AUTOSAR XML (schema 4-2-2)
package /STELLANTIS/EPT/SASWCs
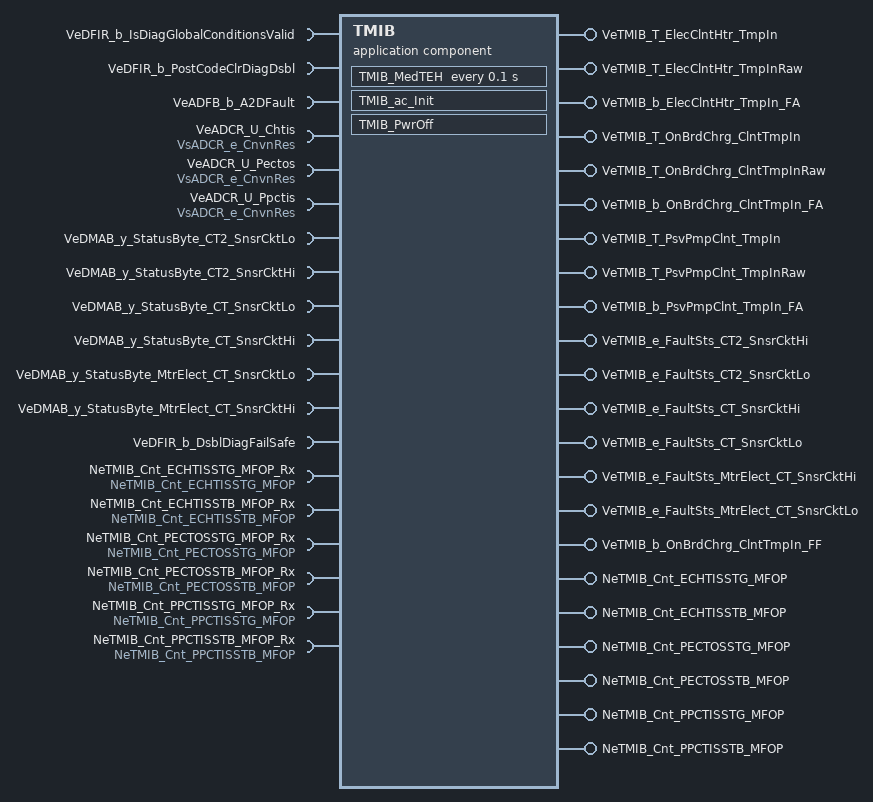
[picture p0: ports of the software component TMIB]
  application sw component type TMIB
    13 x require port:
      VeDFIR_b_IsDiagGlobalConditionsValid: variation-point={short-label=vpVeDFIR_b_IsDiagGlobalConditionsValid, sw-syscond=1}, nonqueued-receiver-com-spec{data-element=Value, init-value=0}, required-interface=VeDFIR_b_IsDiagGlobalConditionsValid
      VeDFIR_b_PostCodeClrDiagDsbl: variation-point={short-label=vpVeDFIR_b_PostCodeClrDiagDsbl, sw-syscond=1}, nonqueued-receiver-com-spec{data-element=Value, init-value=0}, required-interface=VeDFIR_b_PostCodeClrDiagDsbl
      VeADFB_b_A2DFault: variation-point={short-label=vpVeADFB_b_A2DFault, sw-syscond=1}, nonqueued-receiver-com-spec{data-element=Value, init-value=0}, required-interface=VeADFB_b_A2DFault
      VeADCR_U_Chtis: variation-point={short-label=vpVeADCR_U_Chtis, sw-syscond=1}, nonqueued-receiver-com-spec{data-element=VsADCR_e_CnvnRes, init-value={short-label=DefaultInitValue_IDTRAdcInpResData, fields=[0, 0]}}, required-interface=VsADCR_e_CnvnRes
      VeADCR_U_Pectos: variation-point={short-label=vpVeADCR_U_Pectos, sw-syscond=1}, nonqueued-receiver-com-spec{data-element=VsADCR_e_CnvnRes, init-value={short-label=DefaultInitValue_IDTRAdcInpResData, fields=[0, 0]}}, required-interface=VsADCR_e_CnvnRes
      VeADCR_U_Ppctis: variation-point={short-label=vpVeADCR_U_Ppctis, sw-syscond=1}, nonqueued-receiver-com-spec{data-element=VsADCR_e_CnvnRes, init-value={short-label=DefaultInitValue_IDTRAdcInpResData, fields=[0, 0]}}, required-interface=VsADCR_e_CnvnRes
      VeDMAB_y_StatusByte_CT2_SnsrCktLo: variation-point={short-label=vpVeDMAB_y_StatusByte_CT2_SnsrCktLo, sw-syscond=1}, nonqueued-receiver-com-spec{data-element=Value, init-value=0}, required-interface=VeDMAB_y_StatusByte_CT2_SnsrCktLo
      VeDMAB_y_StatusByte_CT2_SnsrCktHi: variation-point={short-label=vpVeDMAB_y_StatusByte_CT2_SnsrCktHi, sw-syscond=1}, nonqueued-receiver-com-spec{data-element=Value, init-value=0}, required-interface=VeDMAB_y_StatusByte_CT2_SnsrCktHi
      VeDMAB_y_StatusByte_CT_SnsrCktLo: variation-point={short-label=vpVeDMAB_y_StatusByte_CT_SnsrCktLo, sw-syscond=1}, nonqueued-receiver-com-spec{data-element=Value, init-value=0}, required-interface=VeDMAB_y_StatusByte_CT_SnsrCktLo
      VeDMAB_y_StatusByte_CT_SnsrCktHi: variation-point={short-label=vpVeDMAB_y_StatusByte_CT_SnsrCktHi, sw-syscond=1}, nonqueued-receiver-com-spec{data-element=Value, init-value=0}, required-interface=VeDMAB_y_StatusByte_CT_SnsrCktHi
      VeDMAB_y_StatusByte_MtrElect_CT_SnsrCktLo: variation-point={short-label=vpVeDMAB_y_StatusByte_MtrElect_CT_SnsrCktLo, sw-syscond=1}, nonqueued-receiver-com-spec{data-element=Value, init-value=0}, required-interface=VeDMAB_y_StatusByte_MtrElect_CT_SnsrCktLo
      VeDMAB_y_StatusByte_MtrElect_CT_SnsrCktHi: variation-point={short-label=vpVeDMAB_y_StatusByte_MtrElect_CT_SnsrCktHi, sw-syscond=1}, nonqueued-receiver-com-spec{data-element=Value, init-value=0}, required-interface=VeDMAB_y_StatusByte_MtrElect_CT_SnsrCktHi
      VeDFIR_b_DsblDiagFailSafe: variation-point={short-label=vpVeDFIR_b_DsblDiagFailSafe, sw-syscond=1}, nonqueued-receiver-com-spec{data-element=Value, init-value=0}, required-interface=VeDFIR_b_DsblDiagFailSafe
    16 x provide port:
      VeTMIB_T_ElecClntHtr_TmpIn: variation-point={short-label=vpVeTMIB_T_ElecClntHtr_TmpIn, sw-syscond=1}, nonqueued-sender-com-spec{data-element=Value, init-value=0}, provided-interface=VeTMIB_T_ElecClntHtr_TmpIn
      VeTMIB_T_ElecClntHtr_TmpInRaw: variation-point={short-label=vpVeTMIB_T_ElecClntHtr_TmpInRaw, sw-syscond=1}, nonqueued-sender-com-spec{data-element=Value, init-value=0}, provided-interface=VeTMIB_T_ElecClntHtr_TmpInRaw
      VeTMIB_b_ElecClntHtr_TmpIn_FA: variation-point={short-label=vpVeTMIB_b_ElecClntHtr_TmpIn_FA, sw-syscond=1}, nonqueued-sender-com-spec{data-element=Value, init-value=0}, provided-interface=VeTMIB_b_ElecClntHtr_TmpIn_FA
      VeTMIB_T_OnBrdChrg_ClntTmpIn: variation-point={short-label=vpVeTMIB_T_OnBrdChrg_ClntTmpIn, sw-syscond=1}, nonqueued-sender-com-spec{data-element=Value, init-value=0}, provided-interface=VeTMIB_T_OnBrdChrg_ClntTmpIn
      VeTMIB_T_OnBrdChrg_ClntTmpInRaw: variation-point={short-label=vpVeTMIB_T_OnBrdChrg_ClntTmpInRaw, sw-syscond=1}, nonqueued-sender-com-spec{data-element=Value, init-value=0}, provided-interface=VeTMIB_T_OnBrdChrg_ClntTmpInRaw
      VeTMIB_b_OnBrdChrg_ClntTmpIn_FA: variation-point={short-label=vpVeTMIB_b_OnBrdChrg_ClntTmpIn_FA, sw-syscond=1}, nonqueued-sender-com-spec{data-element=Value, init-value=0}, provided-interface=VeTMIB_b_OnBrdChrg_ClntTmpIn_FA
      VeTMIB_T_PsvPmpClnt_TmpIn: variation-point={short-label=vpVeTMIB_T_PsvPmpClnt_TmpIn, sw-syscond=1}, nonqueued-sender-com-spec{data-element=Value, init-value=0}, provided-interface=VeTMIB_T_PsvPmpClnt_TmpIn
      VeTMIB_T_PsvPmpClnt_TmpInRaw: variation-point={short-label=vpVeTMIB_T_PsvPmpClnt_TmpInRaw, sw-syscond=1}, nonqueued-sender-com-spec{data-element=Value, init-value=0}, provided-interface=VeTMIB_T_PsvPmpClnt_TmpInRaw
      VeTMIB_b_PsvPmpClnt_TmpIn_FA: variation-point={short-label=vpVeTMIB_b_PsvPmpClnt_TmpIn_FA, sw-syscond=1}, nonqueued-sender-com-spec{data-element=Value, init-value=0}, provided-interface=VeTMIB_b_PsvPmpClnt_TmpIn_FA
      VeTMIB_e_FaultSts_CT2_SnsrCktHi: variation-point={short-label=vpVeTMIB_e_FaultSts_CT2_SnsrCktHi, sw-syscond=1}, nonqueued-sender-com-spec{data-element=Value, init-value=CeDFIB_e_Init}, provided-interface=VeTMIB_e_FaultSts_CT2_SnsrCktHi
      VeTMIB_e_FaultSts_CT2_SnsrCktLo: variation-point={short-label=vpVeTMIB_e_FaultSts_CT2_SnsrCktLo, sw-syscond=1}, nonqueued-sender-com-spec{data-element=Value, init-value=CeDFIB_e_Init}, provided-interface=VeTMIB_e_FaultSts_CT2_SnsrCktLo
      VeTMIB_e_FaultSts_CT_SnsrCktHi: variation-point={short-label=vpVeTMIB_e_FaultSts_CT_SnsrCktHi, sw-syscond=1}, nonqueued-sender-com-spec{data-element=Value, init-value=CeDFIB_e_Init}, provided-interface=VeTMIB_e_FaultSts_CT_SnsrCktHi
      VeTMIB_e_FaultSts_CT_SnsrCktLo: variation-point={short-label=vpVeTMIB_e_FaultSts_CT_SnsrCktLo, sw-syscond=1}, nonqueued-sender-com-spec{data-element=Value, init-value=CeDFIB_e_Init}, provided-interface=VeTMIB_e_FaultSts_CT_SnsrCktLo
      VeTMIB_e_FaultSts_MtrElect_CT_SnsrCktHi: variation-point={short-label=vpVeTMIB_e_FaultSts_MtrElect_CT_SnsrCktHi, sw-syscond=1}, nonqueued-sender-com-spec{data-element=Value, init-value=CeDFIB_e_Init}, provided-interface=VeTMIB_e_FaultSts_MtrElect_CT_SnsrCktHi
      VeTMIB_e_FaultSts_MtrElect_CT_SnsrCktLo: variation-point={short-label=vpVeTMIB_e_FaultSts_MtrElect_CT_SnsrCktLo, sw-syscond=1}, nonqueued-sender-com-spec{data-element=Value, init-value=CeDFIB_e_Init}, provided-interface=VeTMIB_e_FaultSts_MtrElect_CT_SnsrCktLo
      VeTMIB_b_OnBrdChrg_ClntTmpIn_FF: variation-point={short-label=vpVeTMIB_b_OnBrdChrg_ClntTmpIn_FF, sw-syscond=1}, nonqueued-sender-com-spec{data-element=Value, init-value=0}, provided-interface=VeTMIB_b_OnBrdChrg_ClntTmpIn_FF
    6 x require port:
      NeTMIB_Cnt_ECHTISSTG_MFOP_Rx: variation-point={short-label=vpNeTMIB_Cnt_ECHTISSTG_MFOP_Rx, sw-syscond=1}, nv-require-com-spec{init-value=0, variable=NeTMIB_Cnt_ECHTISSTG_MFOP}, required-interface=NeTMIB_Cnt_ECHTISSTG_MFOP
      NeTMIB_Cnt_ECHTISSTB_MFOP_Rx: variation-point={short-label=vpNeTMIB_Cnt_ECHTISSTB_MFOP_Rx, sw-syscond=1}, nv-require-com-spec{init-value=0, variable=NeTMIB_Cnt_ECHTISSTB_MFOP}, required-interface=NeTMIB_Cnt_ECHTISSTB_MFOP
      NeTMIB_Cnt_PECTOSSTG_MFOP_Rx: variation-point={short-label=vpNeTMIB_Cnt_PECTOSSTG_MFOP_Rx, sw-syscond=1}, nv-require-com-spec{init-value=0, variable=NeTMIB_Cnt_PECTOSSTG_MFOP}, required-interface=NeTMIB_Cnt_PECTOSSTG_MFOP
      NeTMIB_Cnt_PECTOSSTB_MFOP_Rx: variation-point={short-label=vpNeTMIB_Cnt_PECTOSSTB_MFOP_Rx, sw-syscond=1}, nv-require-com-spec{init-value=0, variable=NeTMIB_Cnt_PECTOSSTB_MFOP}, required-interface=NeTMIB_Cnt_PECTOSSTB_MFOP
      NeTMIB_Cnt_PPCTISSTG_MFOP_Rx: variation-point={short-label=vpNeTMIB_Cnt_PPCTISSTG_MFOP_Rx, sw-syscond=1}, nv-require-com-spec{init-value=0, variable=NeTMIB_Cnt_PPCTISSTG_MFOP}, required-interface=NeTMIB_Cnt_PPCTISSTG_MFOP
      NeTMIB_Cnt_PPCTISSTB_MFOP_Rx: variation-point={short-label=vpNeTMIB_Cnt_PPCTISSTB_MFOP_Rx, sw-syscond=1}, nv-require-com-spec{init-value=0, variable=NeTMIB_Cnt_PPCTISSTB_MFOP}, required-interface=NeTMIB_Cnt_PPCTISSTB_MFOP
    6 x provide port:
      NeTMIB_Cnt_ECHTISSTG_MFOP: nv-provide-com-spec{ram-block-init-value=0, variable=NeTMIB_Cnt_ECHTISSTG_MFOP}, provided-interface=NeTMIB_Cnt_ECHTISSTG_MFOP
      NeTMIB_Cnt_ECHTISSTB_MFOP: nv-provide-com-spec{ram-block-init-value=0, variable=NeTMIB_Cnt_ECHTISSTB_MFOP}, provided-interface=NeTMIB_Cnt_ECHTISSTB_MFOP
      NeTMIB_Cnt_PECTOSSTG_MFOP: nv-provide-com-spec{ram-block-init-value=0, variable=NeTMIB_Cnt_PECTOSSTG_MFOP}, provided-interface=NeTMIB_Cnt_PECTOSSTG_MFOP
      NeTMIB_Cnt_PECTOSSTB_MFOP: nv-provide-com-spec{ram-block-init-value=0, variable=NeTMIB_Cnt_PECTOSSTB_MFOP}, provided-interface=NeTMIB_Cnt_PECTOSSTB_MFOP
      NeTMIB_Cnt_PPCTISSTG_MFOP: nv-provide-com-spec{ram-block-init-value=0, variable=NeTMIB_Cnt_PPCTISSTG_MFOP}, provided-interface=NeTMIB_Cnt_PPCTISSTG_MFOP
      NeTMIB_Cnt_PPCTISSTB_MFOP: nv-provide-com-spec{ram-block-init-value=0, variable=NeTMIB_Cnt_PPCTISSTB_MFOP}, provided-interface=NeTMIB_Cnt_PPCTISSTB_MFOP
    behavior IB_TMIB: data-type-mapping=[msADTtoIDTMapping, ADTtoIDTMapping], handle-termination-and-restart=NO-SUPPORT
      timing event Event_MedTEH: start-on-event=TMIB_MedTEH, period=0.1
      init event Event_TMIB_ac_Init: start-on-event=TMIB_ac_Init
      init event Event_PwrOff: start-on-event=TMIB_PwrOff
      runnable TMIB_ac_Init
        data-receive-point-by-arguments:
          6 x access:
            IN_NeTMIB_Cnt_ECHTISSTB_MFOP_Rx_NeTMIB_Cnt_ECHTISSTB_MFOP: accessed-variable=NeTMIB_Cnt_ECHTISSTB_MFOP_Rx.NeTMIB_Cnt_ECHTISSTB_MFOP, variation-point={short-label=vpIN_NeTMIB_Cnt_ECHTISSTB_MFOP_Rx_NeTMIB_Cnt_ECHTISSTB_MFOP, sw-syscond=1}
            IN_NeTMIB_Cnt_ECHTISSTG_MFOP_Rx_NeTMIB_Cnt_ECHTISSTG_MFOP: accessed-variable=NeTMIB_Cnt_ECHTISSTG_MFOP_Rx.NeTMIB_Cnt_ECHTISSTG_MFOP, variation-point={short-label=vpIN_NeTMIB_Cnt_ECHTISSTG_MFOP_Rx_NeTMIB_Cnt_ECHTISSTG_MFOP, sw-syscond=1}
            IN_NeTMIB_Cnt_PECTOSSTB_MFOP_Rx_NeTMIB_Cnt_PECTOSSTB_MFOP: accessed-variable=NeTMIB_Cnt_PECTOSSTB_MFOP_Rx.NeTMIB_Cnt_PECTOSSTB_MFOP, variation-point={short-label=vpIN_NeTMIB_Cnt_PECTOSSTB_MFOP_Rx_NeTMIB_Cnt_PECTOSSTB_MFOP, sw-syscond=1}
            IN_NeTMIB_Cnt_PECTOSSTG_MFOP_Rx_NeTMIB_Cnt_PECTOSSTG_MFOP: accessed-variable=NeTMIB_Cnt_PECTOSSTG_MFOP_Rx.NeTMIB_Cnt_PECTOSSTG_MFOP, variation-point={short-label=vpIN_NeTMIB_Cnt_PECTOSSTG_MFOP_Rx_NeTMIB_Cnt_PECTOSSTG_MFOP, sw-syscond=1}
            IN_NeTMIB_Cnt_PPCTISSTB_MFOP_Rx_NeTMIB_Cnt_PPCTISSTB_MFOP: accessed-variable=NeTMIB_Cnt_PPCTISSTB_MFOP_Rx.NeTMIB_Cnt_PPCTISSTB_MFOP, variation-point={short-label=vpIN_NeTMIB_Cnt_PPCTISSTB_MFOP_Rx_NeTMIB_Cnt_PPCTISSTB_MFOP, sw-syscond=1}
            IN_NeTMIB_Cnt_PPCTISSTG_MFOP_Rx_NeTMIB_Cnt_PPCTISSTG_MFOP: accessed-variable=NeTMIB_Cnt_PPCTISSTG_MFOP_Rx.NeTMIB_Cnt_PPCTISSTG_MFOP, variation-point={short-label=vpIN_NeTMIB_Cnt_PPCTISSTG_MFOP_Rx_NeTMIB_Cnt_PPCTISSTG_MFOP, sw-syscond=1}
        data-send-points:
          12 x access:
            OUT_VeTMIB_T_ElecClntHtr_TmpInRaw_Value: accessed-variable=VeTMIB_T_ElecClntHtr_TmpInRaw.Value, variation-point={short-label=vpOUT_VeTMIB_T_ElecClntHtr_TmpInRaw_Value, sw-syscond=1}
            OUT_VeTMIB_T_ElecClntHtr_TmpIn_Value: accessed-variable=VeTMIB_T_ElecClntHtr_TmpIn.Value, variation-point={short-label=vpOUT_VeTMIB_T_ElecClntHtr_TmpIn_Value, sw-syscond=1}
            OUT_VeTMIB_e_FaultSts_CT2_SnsrCktHi_Value: accessed-variable=VeTMIB_e_FaultSts_CT2_SnsrCktHi.Value, variation-point={short-label=vpOUT_VeTMIB_e_FaultSts_CT2_SnsrCktHi_Value, sw-syscond=1}
            OUT_VeTMIB_e_FaultSts_CT2_SnsrCktLo_Value: accessed-variable=VeTMIB_e_FaultSts_CT2_SnsrCktLo.Value, variation-point={short-label=vpOUT_VeTMIB_e_FaultSts_CT2_SnsrCktLo_Value, sw-syscond=1}
            OUT_VeTMIB_T_OnBrdChrg_ClntTmpIn_Value: accessed-variable=VeTMIB_T_OnBrdChrg_ClntTmpIn.Value, variation-point={short-label=vpOUT_VeTMIB_T_OnBrdChrg_ClntTmpIn_Value, sw-syscond=1}
            OUT_VeTMIB_T_OnBrdChrg_ClntTmpInRaw_Value: accessed-variable=VeTMIB_T_OnBrdChrg_ClntTmpInRaw.Value, variation-point={short-label=vpOUT_VeTMIB_T_OnBrdChrg_ClntTmpInRaw_Value, sw-syscond=1}
            OUT_VeTMIB_e_FaultSts_CT_SnsrCktHi_Value: accessed-variable=VeTMIB_e_FaultSts_CT_SnsrCktHi.Value, variation-point={short-label=vpOUT_VeTMIB_e_FaultSts_CT_SnsrCktHi_Value, sw-syscond=1}
            OUT_VeTMIB_e_FaultSts_CT_SnsrCktLo_Value: accessed-variable=VeTMIB_e_FaultSts_CT_SnsrCktLo.Value, variation-point={short-label=vpOUT_VeTMIB_e_FaultSts_CT_SnsrCktLo_Value, sw-syscond=1}
            OUT_VeTMIB_T_PsvPmpClnt_TmpIn_Value: accessed-variable=VeTMIB_T_PsvPmpClnt_TmpIn.Value, variation-point={short-label=vpOUT_VeTMIB_T_PsvPmpClnt_TmpIn_Value, sw-syscond=1}
            OUT_VeTMIB_T_PsvPmpClnt_TmpInRaw_Value: accessed-variable=VeTMIB_T_PsvPmpClnt_TmpInRaw.Value, variation-point={short-label=vpOUT_VeTMIB_T_PsvPmpClnt_TmpInRaw_Value, sw-syscond=1}
            OUT_VeTMIB_e_FaultSts_MtrElect_CT_SnsrCktHi_Value: accessed-variable=VeTMIB_e_FaultSts_MtrElect_CT_SnsrCktHi.Value, variation-point={short-label=vpOUT_VeTMIB_e_FaultSts_MtrElect_CT_SnsrCktHi_Value, sw-syscond=1}
            OUT_VeTMIB_e_FaultSts_MtrElect_CT_SnsrCktLo_Value: accessed-variable=VeTMIB_e_FaultSts_MtrElect_CT_SnsrCktLo.Value, variation-point={short-label=vpOUT_VeTMIB_e_FaultSts_MtrElect_CT_SnsrCktLo_Value, sw-syscond=1}
      runnable TMIB_MedTEH
        data-receive-point-by-arguments:
          13 x access:
            IN_VeADCR_U_Chtis_VsADCR_e_CnvnRes: accessed-variable=VeADCR_U_Chtis.VsADCR_e_CnvnRes, variation-point={short-label=vpIN_VeADCR_U_Chtis_VsADCR_e_CnvnRes, sw-syscond=1}
            IN_VeADCR_U_Pectos_VsADCR_e_CnvnRes: accessed-variable=VeADCR_U_Pectos.VsADCR_e_CnvnRes, variation-point={short-label=vpIN_VeADCR_U_Pectos_VsADCR_e_CnvnRes, sw-syscond=1}
            IN_VeADCR_U_Ppctis_VsADCR_e_CnvnRes: accessed-variable=VeADCR_U_Ppctis.VsADCR_e_CnvnRes, variation-point={short-label=vpIN_VeADCR_U_Ppctis_VsADCR_e_CnvnRes, sw-syscond=1}
            IN_VeADFB_b_A2DFault_Value: accessed-variable=VeADFB_b_A2DFault.Value, variation-point={short-label=vpIN_VeADFB_b_A2DFault_Value, sw-syscond=1}
            IN_VeDFIR_b_DsblDiagFailSafe_Value: accessed-variable=VeDFIR_b_DsblDiagFailSafe.Value, variation-point={short-label=vpIN_VeDFIR_b_DsblDiagFailSafe_Value, sw-syscond=1}
            IN_VeDFIR_b_IsDiagGlobalConditionsValid_Value: accessed-variable=VeDFIR_b_IsDiagGlobalConditionsValid.Value, variation-point={short-label=vpIN_VeDFIR_b_IsDiagGlobalConditionsValid_Value, sw-syscond=1}
            IN_VeDFIR_b_PostCodeClrDiagDsbl_Value: accessed-variable=VeDFIR_b_PostCodeClrDiagDsbl.Value, variation-point={short-label=vpIN_VeDFIR_b_PostCodeClrDiagDsbl_Value, sw-syscond=1}
            IN_VeDMAB_y_StatusByte_CT2_SnsrCktHi_Value: accessed-variable=VeDMAB_y_StatusByte_CT2_SnsrCktHi.Value, variation-point={short-label=vpIN_VeDMAB_y_StatusByte_CT2_SnsrCktHi_Value, sw-syscond=1}
            IN_VeDMAB_y_StatusByte_CT2_SnsrCktLo_Value: accessed-variable=VeDMAB_y_StatusByte_CT2_SnsrCktLo.Value, variation-point={short-label=vpIN_VeDMAB_y_StatusByte_CT2_SnsrCktLo_Value, sw-syscond=1}
            IN_VeDMAB_y_StatusByte_CT_SnsrCktHi_Value: accessed-variable=VeDMAB_y_StatusByte_CT_SnsrCktHi.Value, variation-point={short-label=vpIN_VeDMAB_y_StatusByte_CT_SnsrCktHi_Value, sw-syscond=1}
            IN_VeDMAB_y_StatusByte_CT_SnsrCktLo_Value: accessed-variable=VeDMAB_y_StatusByte_CT_SnsrCktLo.Value, variation-point={short-label=vpIN_VeDMAB_y_StatusByte_CT_SnsrCktLo_Value, sw-syscond=1}
            IN_VeDMAB_y_StatusByte_MtrElect_CT_SnsrCktHi_Value: accessed-variable=VeDMAB_y_StatusByte_MtrElect_CT_SnsrCktHi.Value, variation-point={short-label=vpIN_VeDMAB_y_StatusByte_MtrElect_CT_SnsrCktHi_Value, sw-syscond=1}
            IN_VeDMAB_y_StatusByte_MtrElect_CT_SnsrCktLo_Value: accessed-variable=VeDMAB_y_StatusByte_MtrElect_CT_SnsrCktLo.Value, variation-point={short-label=vpIN_VeDMAB_y_StatusByte_MtrElect_CT_SnsrCktLo_Value, sw-syscond=1}
        data-send-points:
          16 x access:
            OUT_VeTMIB_b_ElecClntHtr_TmpIn_FA_Value: accessed-variable=VeTMIB_b_ElecClntHtr_TmpIn_FA.Value, variation-point={short-label=vpOUT_VeTMIB_b_ElecClntHtr_TmpIn_FA_Value, sw-syscond=1}
            OUT_VeTMIB_T_ElecClntHtr_TmpInRaw_Value: accessed-variable=VeTMIB_T_ElecClntHtr_TmpInRaw.Value, variation-point={short-label=vpOUT_VeTMIB_T_ElecClntHtr_TmpInRaw_Value, sw-syscond=1}
            OUT_VeTMIB_T_ElecClntHtr_TmpIn_Value: accessed-variable=VeTMIB_T_ElecClntHtr_TmpIn.Value, variation-point={short-label=vpOUT_VeTMIB_T_ElecClntHtr_TmpIn_Value, sw-syscond=1}
            OUT_VeTMIB_b_OnBrdChrg_ClntTmpIn_FA_Value: accessed-variable=VeTMIB_b_OnBrdChrg_ClntTmpIn_FA.Value, variation-point={short-label=vpOUT_VeTMIB_b_OnBrdChrg_ClntTmpIn_FA_Value, sw-syscond=1}
            OUT_VeTMIB_T_OnBrdChrg_ClntTmpInRaw_Value: accessed-variable=VeTMIB_T_OnBrdChrg_ClntTmpInRaw.Value, variation-point={short-label=vpOUT_VeTMIB_T_OnBrdChrg_ClntTmpInRaw_Value, sw-syscond=1}
            OUT_VeTMIB_T_OnBrdChrg_ClntTmpIn_Value: accessed-variable=VeTMIB_T_OnBrdChrg_ClntTmpIn.Value, variation-point={short-label=vpOUT_VeTMIB_T_OnBrdChrg_ClntTmpIn_Value, sw-syscond=1}
            OUT_VeTMIB_b_PsvPmpClnt_TmpIn_FA_Value: accessed-variable=VeTMIB_b_PsvPmpClnt_TmpIn_FA.Value, variation-point={short-label=vpOUT_VeTMIB_b_PsvPmpClnt_TmpIn_FA_Value, sw-syscond=1}
            OUT_VeTMIB_T_PsvPmpClnt_TmpInRaw_Value: accessed-variable=VeTMIB_T_PsvPmpClnt_TmpInRaw.Value, variation-point={short-label=vpOUT_VeTMIB_T_PsvPmpClnt_TmpInRaw_Value, sw-syscond=1}
            OUT_VeTMIB_T_PsvPmpClnt_TmpIn_Value: accessed-variable=VeTMIB_T_PsvPmpClnt_TmpIn.Value, variation-point={short-label=vpOUT_VeTMIB_T_PsvPmpClnt_TmpIn_Value, sw-syscond=1}
            OUT_VeTMIB_e_FaultSts_CT2_SnsrCktHi_Value: accessed-variable=VeTMIB_e_FaultSts_CT2_SnsrCktHi.Value, variation-point={short-label=vpOUT_VeTMIB_e_FaultSts_CT2_SnsrCktHi_Value, sw-syscond=1}
            OUT_VeTMIB_e_FaultSts_CT2_SnsrCktLo_Value: accessed-variable=VeTMIB_e_FaultSts_CT2_SnsrCktLo.Value, variation-point={short-label=vpOUT_VeTMIB_e_FaultSts_CT2_SnsrCktLo_Value, sw-syscond=1}
            OUT_VeTMIB_e_FaultSts_CT_SnsrCktHi_Value: accessed-variable=VeTMIB_e_FaultSts_CT_SnsrCktHi.Value, variation-point={short-label=vpOUT_VeTMIB_e_FaultSts_CT_SnsrCktHi_Value, sw-syscond=1}
            OUT_VeTMIB_e_FaultSts_CT_SnsrCktLo_Value: accessed-variable=VeTMIB_e_FaultSts_CT_SnsrCktLo.Value, variation-point={short-label=vpOUT_VeTMIB_e_FaultSts_CT_SnsrCktLo_Value, sw-syscond=1}
            OUT_VeTMIB_e_FaultSts_MtrElect_CT_SnsrCktHi_Value: accessed-variable=VeTMIB_e_FaultSts_MtrElect_CT_SnsrCktHi.Value, variation-point={short-label=vpOUT_VeTMIB_e_FaultSts_MtrElect_CT_SnsrCktHi_Value, sw-syscond=1}
            OUT_VeTMIB_e_FaultSts_MtrElect_CT_SnsrCktLo_Value: accessed-variable=VeTMIB_e_FaultSts_MtrElect_CT_SnsrCktLo.Value, variation-point={short-label=vpOUT_VeTMIB_e_FaultSts_MtrElect_CT_SnsrCktLo_Value, sw-syscond=1}
            OUT_VeTMIB_b_OnBrdChrg_ClntTmpIn_FF_Value: accessed-variable=VeTMIB_b_OnBrdChrg_ClntTmpIn_FF.Value, variation-point={short-label=vpOUT_VeTMIB_b_OnBrdChrg_ClntTmpIn_FF_Value, sw-syscond=1}
      runnable TMIB_PwrOff
        data-send-points:
          6 x access:
            OUT_NeTMIB_Cnt_ECHTISSTG_MFOP_NeTMIB_Cnt_ECHTISSTG_MFOP: accessed-variable=NeTMIB_Cnt_ECHTISSTG_MFOP.NeTMIB_Cnt_ECHTISSTG_MFOP
            OUT_NeTMIB_Cnt_ECHTISSTB_MFOP_NeTMIB_Cnt_ECHTISSTB_MFOP: accessed-variable=NeTMIB_Cnt_ECHTISSTB_MFOP.NeTMIB_Cnt_ECHTISSTB_MFOP
            OUT_NeTMIB_Cnt_PECTOSSTG_MFOP_NeTMIB_Cnt_PECTOSSTG_MFOP: accessed-variable=NeTMIB_Cnt_PECTOSSTG_MFOP.NeTMIB_Cnt_PECTOSSTG_MFOP
            OUT_NeTMIB_Cnt_PECTOSSTB_MFOP_NeTMIB_Cnt_PECTOSSTB_MFOP: accessed-variable=NeTMIB_Cnt_PECTOSSTB_MFOP.NeTMIB_Cnt_PECTOSSTB_MFOP
            OUT_NeTMIB_Cnt_PPCTISSTG_MFOP_NeTMIB_Cnt_PPCTISSTG_MFOP: accessed-variable=NeTMIB_Cnt_PPCTISSTG_MFOP.NeTMIB_Cnt_PPCTISSTG_MFOP
            OUT_NeTMIB_Cnt_PPCTISSTB_MFOP_NeTMIB_Cnt_PPCTISSTB_MFOP: accessed-variable=NeTMIB_Cnt_PPCTISSTB_MFOP.NeTMIB_Cnt_PPCTISSTB_MFOP
      variation point proxy Variant_TMIB_ECHTIS_Presence: category=CONDITION, condition-access=1
      variation point proxy Variant_TMIB_PECTOS_Presence: category=CONDITION, condition-access=1
      variation point proxy Variant_TMIB_PPCTIS_Presence: category=CONDITION, condition-access=1
